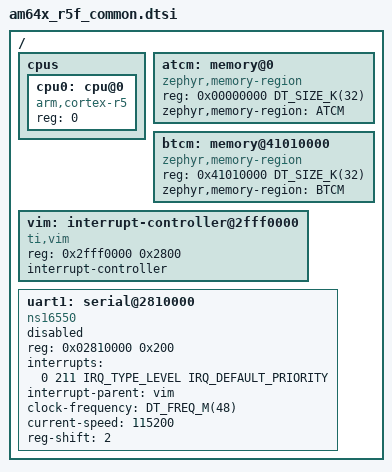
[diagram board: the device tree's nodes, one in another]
/*
 * Copyright (c) 2024 Texas Instruments Incorporated
 *
 * SPDX-License-Identifier: Apache-2.0
 */

#include <mem.h>
#include <freq.h>
#include <arm/armv7-r.dtsi>
#include <zephyr/dt-bindings/interrupt-controller/ti-vim.h>

/ {
	cpus {
		#address-cells = <1>;
		#size-cells = <0>;

		cpu0: cpu@0 {
			device_type = "cpu";
			compatible = "arm,cortex-r5";
			reg = <0>;
		};
	};

	atcm: memory@0 {
		device_type = "memory";
		compatible = "zephyr,memory-region", "mmio-sram";
		reg = <0x00000000 DT_SIZE_K(32)>;
		zephyr,memory-region = "ATCM";
	};

	btcm: memory@41010000 {
		device_type = "memory";
		compatible = "zephyr,memory-region", "mmio-sram";
		reg = <0x41010000 DT_SIZE_K(32)>;
		zephyr,memory-region = "BTCM";
	};

	vim: interrupt-controller@2fff0000 {
		#address-cells = <1>;
		compatible = "ti,vim";
		reg = <0x2fff0000 0x2800>;
		interrupt-controller;
		#interrupt-cells = <4>; /* {IRQ/FIQ, IRQ_NUM, IRQ_TYPE, IRQ_PRIO} */
		status = "okay";
	};

	uart1: serial@2810000 {
		compatible = "ns16550";
		reg = <0x02810000 0x200>;
		interrupts = <0 211 IRQ_TYPE_LEVEL IRQ_DEFAULT_PRIORITY>;
		interrupt-parent = <&vim>;
		clock-frequency = <DT_FREQ_M(48)>;
		current-speed = <115200>;
		reg-shift = <2>;
		status = "disabled";
	};
};
